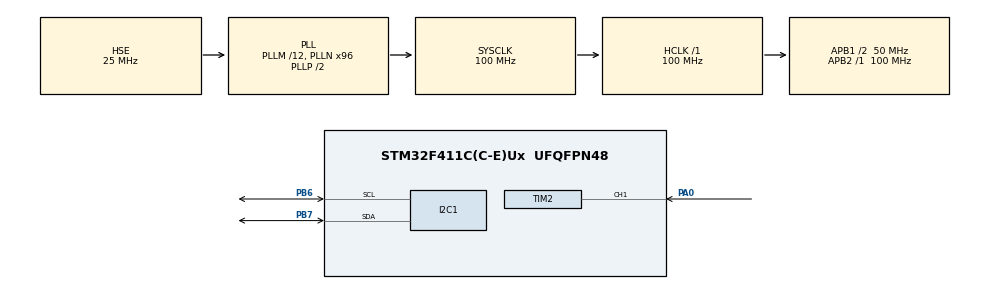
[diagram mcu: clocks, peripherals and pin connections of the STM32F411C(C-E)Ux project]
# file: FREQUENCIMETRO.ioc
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Mcu.Family=STM32F4
Mcu.Name=STM32F411C(C-E)Ux
Mcu.Package=UFQFPN48
NVIC.PriorityGroup=NVIC_PRIORITYGROUP_4
NVIC.TIM2_IRQn=true\:0\:0\:false\:false\:true\:true\:true\:true
PA0-WKUP.Signal=S_TIM2_CH1_ETR
PA13.Mode=Serial_Wire
PA13.Signal=SYS_JTMS-SWDIO
PA14.Mode=Serial_Wire
PA14.Signal=SYS_JTCK-SWCLK
PB6.Mode=I2C
PB6.Signal=I2C1_SCL
PB7.Mode=I2C
PB7.Signal=I2C1_SDA
PH0\ -\ OSC_IN.Mode=HSE-External-Oscillator
PH0\ -\ OSC_IN.Signal=RCC_OSC_IN
PH1\ -\ OSC_OUT.Mode=HSE-External-Oscillator
PH1\ -\ OSC_OUT.Signal=RCC_OSC_OUT
ProjectManager.HeapSize=0x200
ProjectManager.StackSize=0x400
ProjectManager.TargetToolchain=STM32CubeIDE
RCC.48MHZClocksFreq_Value=50000000
RCC.AHBFreq_Value=100000000
RCC.APB1CLKDivider=RCC_HCLK_DIV2
RCC.APB1Freq_Value=50000000
RCC.APB1TimFreq_Value=100000000
RCC.APB2Freq_Value=100000000
RCC.APB2TimFreq_Value=100000000
RCC.CortexFreq_Value=100000000
RCC.HCLKFreq_Value=100000000
RCC.HSE_VALUE=25000000
RCC.HSI_VALUE=16000000
RCC.LSE_VALUE=32768
RCC.PLLM=12
RCC.PLLN=96
RCC.PLLSourceVirtual=RCC_PLLSOURCE_HSE
RCC.SYSCLKFreq_VALUE=100000000
RCC.SYSCLKSource=RCC_SYSCLKSOURCE_PLLCLK
RCC.VCOOutputFreq_Value=200000000
SH.S_TIM2_CH1_ETR.0=TIM2_CH1,Input_Capture1_from_TI1
TIM2.Channel-Input_Capture1_from_TI1=TIM_CHANNEL_1
TIM2.ICPolarity_CH1=TIM_INPUTCHANNELPOLARITY_RISING
VP_TIM2_VS_ClockSourceINT.Mode=Internal
board=custom

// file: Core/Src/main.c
/* USER CODE BEGIN Header */
/**
 ******************************************************************************
 * @file           : main.c
 * @brief          : Main program body
 ******************************************************************************
 * @attention
 *
 * Copyright (c) 2023 STMicroelectronics.
 * All rights reserved.
 *
 * This software is licensed under terms that can be found in the LICENSE file
 * in the root directory of this software component.
 * If no LICENSE file comes with this software, it is provided AS-IS.
 *
 ******************************************************************************
 */
/* USER CODE END Header */
#include "main.h"

/* USER CODE BEGIN Includes */
#include "LCD_I2C.h"
#include "stdio.h"
#include "string.h"
#include "math.h"
/* USER CODE END Includes */

/* USER CODE BEGIN PD */
#define Linha_1 (0x80 | 0x00)
#define Linha_2 (0x80 | 0x40)
#define Linha_3 (0x80 | 0x14)
#define Linha_4 (0x80 | 0x54)
/* USER CODE END PD */

I2C_HandleTypeDef hi2c1;

TIM_HandleTypeDef htim2;

/* USER CODE BEGIN PV */
uint32_t CCR_anter, CCR_atual, diferenca, CLOCK;
uint8_t flag = 0; // "0" se primeira captura
char valor_string[6];
double frequencia;

/* USER CODE END PV */

void SystemClock_Config(void);
static void MX_GPIO_Init(void);
static void MX_TIM2_Init(void);
static void MX_I2C1_Init(void);

int main(void)
{

  /* MCU Configuration--------------------------------------------------------*/

  /* Reset of all peripherals, Initializes the Flash interface and the Systick. */
  HAL_Init();

  /* Configure the system clock */
  SystemClock_Config();

  /* Initialize all configured peripherals */
  MX_GPIO_Init();
  MX_TIM2_Init();
  MX_I2C1_Init();
  /* USER CODE BEGIN 2 */
	lcd_init();
	HAL_TIM_IC_Start_IT(&htim2, TIM_CHANNEL_1);
	CLOCK = HAL_RCC_GetSysClockFreq();
  /* USER CODE END 2 */

  /* Infinite loop */
  /* USER CODE BEGIN WHILE */
	while (1) {
		lcd_send_cmd(Linha_1);
		lcd_send_string("Freq =");

		if (frequencia < 1000) {
			sprintf(valor_string, "%.1f", frequencia);
			lcd_send_cmd(Linha_1 + 7);
			lcd_send_string(valor_string);
			lcd_send_cmd(Linha_1 + 12);
			lcd_send_string(" [Hz]");
		}

		if ((frequencia >= 1000) & (frequencia <= 9999)) {
			sprintf(valor_string, "%.3f", frequencia / 1000);
			lcd_send_cmd(Linha_1 + 7);
			lcd_send_string(valor_string);
			lcd_send_cmd(Linha_1 + 12);
			lcd_send_string(" [KHz]");
		}

		if ((frequencia >= 10000) & (frequencia <= 99999)) {
			sprintf(valor_string, "%.3f", frequencia / 1000);
			lcd_send_cmd(Linha_1 + 7);
			lcd_send_string(valor_string);
			lcd_send_cmd(Linha_1 + 13);
			lcd_send_string(" [KHz]");
		}

		if (frequencia >= 100000) {
			sprintf(valor_string, "%.1f", frequencia / 1000);
			lcd_send_cmd(Linha_1 + 7);
			lcd_send_string(valor_string);
			lcd_send_cmd(Linha_1 + 13);
			lcd_send_string(" [KHz]");
		}

		lcd_send_cmd(Linha_3);
		lcd_send_string("T = ");
		sprintf(valor_string, "%li", diferenca);
		lcd_send_cmd(Linha_3 + 4);
		lcd_send_string(valor_string);
		lcd_send_cmd(Linha_3 + 12);
		lcd_send_string("Ciclos");

		lcd_send_cmd(Linha_4);
		lcd_send_string("Clock = ");
		lcd_send_cmd(Linha_4 + 8);
		sprintf(valor_string, "%li", CLOCK / 1000000);
		lcd_send_string(valor_string);
		lcd_send_string(" [MHz]");
		lcd_send_cmd(Linha_4 + 12);

		HAL_Delay(1000);

		lcd_clear();
    /* USER CODE END WHILE */

	}
}

void SystemClock_Config(void)
{
  RCC_OscInitTypeDef RCC_OscInitStruct = {0};
  RCC_ClkInitTypeDef RCC_ClkInitStruct = {0};

  /** Configure the main internal regulator output voltage
  */
  __HAL_RCC_PWR_CLK_ENABLE();
  __HAL_PWR_VOLTAGESCALING_CONFIG(PWR_REGULATOR_VOLTAGE_SCALE1);

  /** Initializes the RCC Oscillators according to the specified parameters
  * in the RCC_OscInitTypeDef structure.
  */
  RCC_OscInitStruct.OscillatorType = RCC_OSCILLATORTYPE_HSE;
  RCC_OscInitStruct.HSEState = RCC_HSE_ON;
  RCC_OscInitStruct.PLL.PLLState = RCC_PLL_ON;
  RCC_OscInitStruct.PLL.PLLSource = RCC_PLLSOURCE_HSE;
  RCC_OscInitStruct.PLL.PLLM = 12;
  RCC_OscInitStruct.PLL.PLLN = 96;
  RCC_OscInitStruct.PLL.PLLP = RCC_PLLP_DIV2;
  RCC_OscInitStruct.PLL.PLLQ = 4;
  if (HAL_RCC_OscConfig(&RCC_OscInitStruct) != HAL_OK)
  {
    Error_Handler();
  }

  /** Initializes the CPU, AHB and APB buses clocks
  */
  RCC_ClkInitStruct.ClockType = RCC_CLOCKTYPE_HCLK|RCC_CLOCKTYPE_SYSCLK
                              |RCC_CLOCKTYPE_PCLK1|RCC_CLOCKTYPE_PCLK2;
  RCC_ClkInitStruct.SYSCLKSource = RCC_SYSCLKSOURCE_PLLCLK;
  RCC_ClkInitStruct.AHBCLKDivider = RCC_SYSCLK_DIV1;
  RCC_ClkInitStruct.APB1CLKDivider = RCC_HCLK_DIV2;
  RCC_ClkInitStruct.APB2CLKDivider = RCC_HCLK_DIV1;

  if (HAL_RCC_ClockConfig(&RCC_ClkInitStruct, FLASH_LATENCY_3) != HAL_OK)
  {
    Error_Handler();
  }
}

static void MX_I2C1_Init(void)
{

  hi2c1.Instance = I2C1;
  hi2c1.Init.ClockSpeed = 100000;
  hi2c1.Init.DutyCycle = I2C_DUTYCYCLE_2;
  hi2c1.Init.OwnAddress1 = 0;
  hi2c1.Init.AddressingMode = I2C_ADDRESSINGMODE_7BIT;
  hi2c1.Init.DualAddressMode = I2C_DUALADDRESS_DISABLE;
  hi2c1.Init.OwnAddress2 = 0;
  hi2c1.Init.GeneralCallMode = I2C_GENERALCALL_DISABLE;
  hi2c1.Init.NoStretchMode = I2C_NOSTRETCH_DISABLE;
  if (HAL_I2C_Init(&hi2c1) != HAL_OK)
  {
    Error_Handler();
  }

}

static void MX_TIM2_Init(void)
{

  TIM_ClockConfigTypeDef sClockSourceConfig = {0};
  TIM_MasterConfigTypeDef sMasterConfig = {0};
  TIM_IC_InitTypeDef sConfigIC = {0};

  htim2.Instance = TIM2;
  htim2.Init.Prescaler = 0;
  htim2.Init.CounterMode = TIM_COUNTERMODE_UP;
  htim2.Init.Period = 4294967295;
  htim2.Init.ClockDivision = TIM_CLOCKDIVISION_DIV1;
  htim2.Init.AutoReloadPreload = TIM_AUTORELOAD_PRELOAD_DISABLE;
  if (HAL_TIM_Base_Init(&htim2) != HAL_OK)
  {
    Error_Handler();
  }
  sClockSourceConfig.ClockSource = TIM_CLOCKSOURCE_INTERNAL;
  if (HAL_TIM_ConfigClockSource(&htim2, &sClockSourceConfig) != HAL_OK)
  {
    Error_Handler();
  }
  if (HAL_TIM_IC_Init(&htim2) != HAL_OK)
  {
    Error_Handler();
  }
  sMasterConfig.MasterOutputTrigger = TIM_TRGO_RESET;
  sMasterConfig.MasterSlaveMode = TIM_MASTERSLAVEMODE_DISABLE;
  if (HAL_TIMEx_MasterConfigSynchronization(&htim2, &sMasterConfig) != HAL_OK)
  {
    Error_Handler();
  }
  sConfigIC.ICPolarity = TIM_INPUTCHANNELPOLARITY_RISING;
  sConfigIC.ICSelection = TIM_ICSELECTION_DIRECTTI;
  sConfigIC.ICPrescaler = TIM_ICPSC_DIV1;
  sConfigIC.ICFilter = 0;
  if (HAL_TIM_IC_ConfigChannel(&htim2, &sConfigIC, TIM_CHANNEL_1) != HAL_OK)
  {
    Error_Handler();
  }

}

static void MX_GPIO_Init(void)
{

  /* GPIO Ports Clock Enable */
  __HAL_RCC_GPIOH_CLK_ENABLE();
  __HAL_RCC_GPIOA_CLK_ENABLE();
  __HAL_RCC_GPIOB_CLK_ENABLE();

}

/* USER CODE BEGIN 4 */
void HAL_TIM_IC_CaptureCallback(TIM_HandleTypeDef *htim) {
	if (htim->Channel == HAL_TIM_ACTIVE_CHANNEL_1) {
		switch (flag) {
		case 0:
			CCR_anter = HAL_TIM_ReadCapturedValue(htim, TIM_CHANNEL_1);
			flag = 1;
			break;
		case 1:
			CCR_atual = HAL_TIM_ReadCapturedValue(htim, TIM_CHANNEL_1);
			if (CCR_atual > CCR_anter)
				diferenca = CCR_atual - CCR_anter;
			else
				diferenca = ((0xFFFFFFFF - CCR_anter) + CCR_atual);
			__HAL_TIM_SET_COUNTER(htim, 0);
			flag = 0;
			break;
		default:
			__NOP();
		}

		frequencia = ((double) CLOCK / (double) diferenca);
	}
}
/* USER CODE END 4 */

void Error_Handler(void)
{
	__disable_irq();
	while (1) {
	}
}
